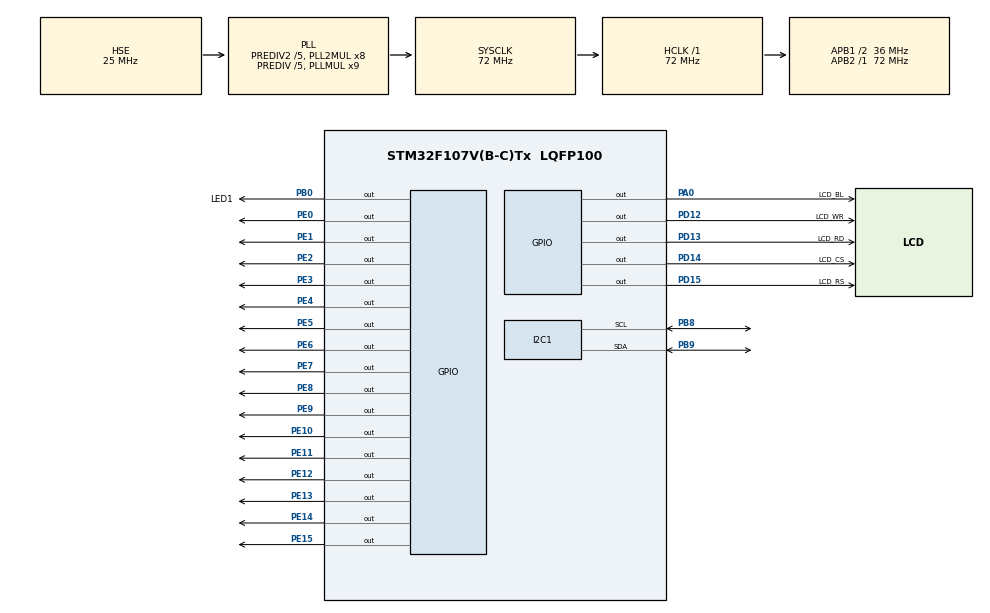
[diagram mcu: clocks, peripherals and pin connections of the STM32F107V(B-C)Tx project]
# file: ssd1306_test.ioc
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I2C1.I2C_Mode=I2C_Fast
Mcu.Family=STM32F1
Mcu.Name=STM32F107V(B-C)Tx
Mcu.Package=LQFP100
NVIC.PriorityGroup=NVIC_PRIORITYGROUP_4
OSC_IN.Mode=HSE-External-Oscillator
OSC_IN.Signal=RCC_OSC_IN
OSC_OUT.Mode=HSE-External-Oscillator
OSC_OUT.Signal=RCC_OSC_OUT
PA0-WKUP.GPIO_Label=LCD_BL
PA0-WKUP.GPIO_PuPd=GPIO_PULLDOWN
PA0-WKUP.Signal=GPIO_Output
PA13.Mode=Serial_Wire
PA13.Signal=SYS_JTMS-SWDIO
PA14.Mode=Serial_Wire
PA14.Signal=SYS_JTCK-SWCLK
PB0.GPIO_Label=LED1
PB0.Signal=GPIO_Output
PB8.Mode=I2C
PB8.Signal=I2C1_SCL
PB9.Mode=I2C
PB9.Signal=I2C1_SDA
PD12.GPIO_Label=LCD_WR
PD12.Signal=GPIO_Output
PD13.GPIO_Label=LCD_RD
PD13.Signal=GPIO_Output
PD14.GPIO_Label=LCD_CS
PD14.Signal=GPIO_Output
PD15.GPIO_Label=LCD_RS
PD15.Signal=GPIO_Output
PE0.Signal=GPIO_Output
PE1.Signal=GPIO_Output
PE10.Signal=GPIO_Output
PE11.Signal=GPIO_Output
PE12.Signal=GPIO_Output
PE13.Signal=GPIO_Output
PE14.Signal=GPIO_Output
PE15.Signal=GPIO_Output
PE2.Signal=GPIO_Output
PE3.Signal=GPIO_Output
PE4.Signal=GPIO_Output
PE5.Signal=GPIO_Output
PE6.Signal=GPIO_Output
PE7.Signal=GPIO_Output
PE8.Signal=GPIO_Output
PE9.Signal=GPIO_Output
ProjectManager.HeapSize=0x200
ProjectManager.StackSize=0x400
ProjectManager.TargetToolchain=TrueSTUDIO
RCC.AHBFreq_Value=72000000
RCC.APB1CLKDivider=RCC_HCLK_DIV2
RCC.APB1Freq_Value=36000000
RCC.APB1TimFreq_Value=72000000
RCC.APB2Freq_Value=72000000
RCC.APB2TimFreq_Value=72000000
RCC.HCLKFreq_Value=72000000
RCC.HSEDivPLL=RCC_HSE_PREDIV_DIV5
RCC.HSE_VALUE=25000000
RCC.PLLMUL=RCC_PLL_MUL9
RCC.PLLSourceVirtual=RCC_PLLSOURCE_HSE
RCC.Prediv1Source=RCC_PREDIV1_SOURCE_PLL2
RCC.Prediv2=RCC_HSE_PREDIV2_DIV5
RCC.SYSCLKFreq_VALUE=72000000
RCC.SYSCLKSource=RCC_SYSCLKSOURCE_PLLCLK
RCC.USBFreq_Value=48000000
board=custom

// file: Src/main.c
/**
  ******************************************************************************
  * @file           : main.c
  * @brief          : Main program body
  ******************************************************************************
  ** This notice applies to any and all portions of this file
  * that are not between comment pairs USER CODE BEGIN and
  * USER CODE END. Other portions of this file, whether
  * inserted by the user or by software development tools
  * are owned by their respective copyright owners.
  *
  * COPYRIGHT(c) 2018 STMicroelectronics
  *
  * Redistribution and use in source and binary forms, with or without modification,
  * are permitted provided that the following conditions are met:
  *   1. Redistributions of source code must retain the above copyright notice,
  *      this list of conditions and the following disclaimer.
  *   2. Redistributions in binary form must reproduce the above copyright notice,
  *      this list of conditions and the following disclaimer in the documentation
  *      and/or other materials provided with the distribution.
  *   3. Neither the name of STMicroelectronics nor the names of its contributors
  *      may be used to endorse or promote products derived from this software
  *      without specific prior written permission.
  *
  * THIS SOFTWARE IS PROVIDED BY THE COPYRIGHT HOLDERS AND CONTRIBUTORS "AS IS"
  * AND ANY EXPRESS OR IMPLIED WARRANTIES, INCLUDING, BUT NOT LIMITED TO, THE
  * IMPLIED WARRANTIES OF MERCHANTABILITY AND FITNESS FOR A PARTICULAR PURPOSE ARE
  * DISCLAIMED. IN NO EVENT SHALL THE COPYRIGHT HOLDER OR CONTRIBUTORS BE LIABLE
  * FOR ANY DIRECT, INDIRECT, INCIDENTAL, SPECIAL, EXEMPLARY, OR CONSEQUENTIAL
  * DAMAGES (INCLUDING, BUT NOT LIMITED TO, PROCUREMENT OF SUBSTITUTE GOODS OR
  * SERVICES; LOSS OF USE, DATA, OR PROFITS; OR BUSINESS INTERRUPTION) HOWEVER
  * CAUSED AND ON ANY THEORY OF LIABILITY, WHETHER IN CONTRACT, STRICT LIABILITY,
  * OR TORT (INCLUDING NEGLIGENCE OR OTHERWISE) ARISING IN ANY WAY OUT OF THE USE
  * OF THIS SOFTWARE, EVEN IF ADVISED OF THE POSSIBILITY OF SUCH DAMAGE.
  *
  ******************************************************************************
  */
#include "main.h"
#include "stm32f1xx_hal.h"

/* USER CODE BEGIN Includes */
#include "app.h"
/* USER CODE END Includes */

I2C_HandleTypeDef hi2c1;

/* USER CODE BEGIN PV */
/* Private variables ---------------------------------------------------------*/

/* USER CODE END PV */

void SystemClock_Config(void);
static void MX_GPIO_Init(void);
static void MX_I2C1_Init(void);

/* USER CODE BEGIN PFP */
/* Private function prototypes -----------------------------------------------*/

/* USER CODE END PFP */

int main(void)
{

  /* MCU Configuration----------------------------------------------------------*/

  /* Reset of all peripherals, Initializes the Flash interface and the Systick. */
  HAL_Init();

  /* Configure the system clock */
  SystemClock_Config();

  /* Initialize all configured peripherals */
  MX_GPIO_Init();
  MX_I2C1_Init();
  /* USER CODE BEGIN 2 */
  app_init();
  /* USER CODE END 2 */

  /* Infinite loop */
  while (1)
  {

  /* USER CODE BEGIN 3 */
	app_step();
  }
  /* USER CODE END 3 */

}

void SystemClock_Config(void)
{

  RCC_OscInitTypeDef RCC_OscInitStruct;
  RCC_ClkInitTypeDef RCC_ClkInitStruct;

    /**Initializes the CPU, AHB and APB busses clocks
    */
  RCC_OscInitStruct.OscillatorType = RCC_OSCILLATORTYPE_HSE;
  RCC_OscInitStruct.HSEState = RCC_HSE_ON;
  RCC_OscInitStruct.HSEPredivValue = RCC_HSE_PREDIV_DIV5;
  RCC_OscInitStruct.HSIState = RCC_HSI_ON;
  RCC_OscInitStruct.Prediv1Source = RCC_PREDIV1_SOURCE_PLL2;
  RCC_OscInitStruct.PLL.PLLState = RCC_PLL_ON;
  RCC_OscInitStruct.PLL.PLLSource = RCC_PLLSOURCE_HSE;
  RCC_OscInitStruct.PLL.PLLMUL = RCC_PLL_MUL9;
  RCC_OscInitStruct.PLL2.PLL2State = RCC_PLL2_ON;
  RCC_OscInitStruct.PLL2.PLL2MUL = RCC_PLL2_MUL8;
  RCC_OscInitStruct.PLL2.HSEPrediv2Value = RCC_HSE_PREDIV2_DIV5;
  if (HAL_RCC_OscConfig(&RCC_OscInitStruct) != HAL_OK)
  {
    _Error_Handler(__FILE__, __LINE__);
  }

    /**Initializes the CPU, AHB and APB busses clocks
    */
  RCC_ClkInitStruct.ClockType = RCC_CLOCKTYPE_HCLK|RCC_CLOCKTYPE_SYSCLK
                              |RCC_CLOCKTYPE_PCLK1|RCC_CLOCKTYPE_PCLK2;
  RCC_ClkInitStruct.SYSCLKSource = RCC_SYSCLKSOURCE_PLLCLK;
  RCC_ClkInitStruct.AHBCLKDivider = RCC_SYSCLK_DIV1;
  RCC_ClkInitStruct.APB1CLKDivider = RCC_HCLK_DIV2;
  RCC_ClkInitStruct.APB2CLKDivider = RCC_HCLK_DIV1;

  if (HAL_RCC_ClockConfig(&RCC_ClkInitStruct, FLASH_LATENCY_2) != HAL_OK)
  {
    _Error_Handler(__FILE__, __LINE__);
  }

    /**Configure the Systick interrupt time
    */
  HAL_SYSTICK_Config(HAL_RCC_GetHCLKFreq()/1000);

    /**Configure the Systick
    */
  HAL_SYSTICK_CLKSourceConfig(SYSTICK_CLKSOURCE_HCLK);

    /**Configure the Systick interrupt time
    */
  __HAL_RCC_PLLI2S_ENABLE();

  /* SysTick_IRQn interrupt configuration */
  HAL_NVIC_SetPriority(SysTick_IRQn, 0, 0);
}

/* I2C1 init function */
static void MX_I2C1_Init(void)
{

  hi2c1.Instance = I2C1;
  hi2c1.Init.ClockSpeed = 400000;
  hi2c1.Init.DutyCycle = I2C_DUTYCYCLE_2;
  hi2c1.Init.OwnAddress1 = 0;
  hi2c1.Init.AddressingMode = I2C_ADDRESSINGMODE_7BIT;
  hi2c1.Init.DualAddressMode = I2C_DUALADDRESS_DISABLE;
  hi2c1.Init.OwnAddress2 = 0;
  hi2c1.Init.GeneralCallMode = I2C_GENERALCALL_DISABLE;
  hi2c1.Init.NoStretchMode = I2C_NOSTRETCH_DISABLE;
  if (HAL_I2C_Init(&hi2c1) != HAL_OK)
  {
    _Error_Handler(__FILE__, __LINE__);
  }

}

/** Configure pins as
        * Analog
        * Input
        * Output
        * EVENT_OUT
        * EXTI
*/
static void MX_GPIO_Init(void)
{

  GPIO_InitTypeDef GPIO_InitStruct;

  /* GPIO Ports Clock Enable */
  __HAL_RCC_GPIOE_CLK_ENABLE();
  __HAL_RCC_GPIOA_CLK_ENABLE();
  __HAL_RCC_GPIOB_CLK_ENABLE();
  __HAL_RCC_GPIOD_CLK_ENABLE();

  /*Configure GPIO pin Output Level */
  HAL_GPIO_WritePin(GPIOE, GPIO_PIN_2|GPIO_PIN_3|GPIO_PIN_4|GPIO_PIN_5
                          |GPIO_PIN_6|GPIO_PIN_7|GPIO_PIN_8|GPIO_PIN_9
                          |GPIO_PIN_10|GPIO_PIN_11|GPIO_PIN_12|GPIO_PIN_13
                          |GPIO_PIN_14|GPIO_PIN_15|GPIO_PIN_0|GPIO_PIN_1, GPIO_PIN_RESET);

  /*Configure GPIO pin Output Level */
  HAL_GPIO_WritePin(LCD_BL_GPIO_Port, LCD_BL_Pin, GPIO_PIN_RESET);

  /*Configure GPIO pin Output Level */
  HAL_GPIO_WritePin(LED1_GPIO_Port, LED1_Pin, GPIO_PIN_RESET);

  /*Configure GPIO pin Output Level */
  HAL_GPIO_WritePin(GPIOD, LCD_WR_Pin|LCD_RD_Pin|LCD_CS_Pin|LCD_RS_Pin, GPIO_PIN_RESET);

  /*Configure GPIO pins : PE2 PE3 PE4 PE5
                           PE6 PE7 PE8 PE9
                           PE10 PE11 PE12 PE13
                           PE14 PE15 PE0 PE1 */
  GPIO_InitStruct.Pin = GPIO_PIN_2|GPIO_PIN_3|GPIO_PIN_4|GPIO_PIN_5
                          |GPIO_PIN_6|GPIO_PIN_7|GPIO_PIN_8|GPIO_PIN_9
                          |GPIO_PIN_10|GPIO_PIN_11|GPIO_PIN_12|GPIO_PIN_13
                          |GPIO_PIN_14|GPIO_PIN_15|GPIO_PIN_0|GPIO_PIN_1;
  GPIO_InitStruct.Mode = GPIO_MODE_OUTPUT_PP;
  GPIO_InitStruct.Pull = GPIO_NOPULL;
  GPIO_InitStruct.Speed = GPIO_SPEED_FREQ_LOW;
  HAL_GPIO_Init(GPIOE, &GPIO_InitStruct);

  /*Configure GPIO pin : LCD_BL_Pin */
  GPIO_InitStruct.Pin = LCD_BL_Pin;
  GPIO_InitStruct.Mode = GPIO_MODE_OUTPUT_PP;
  GPIO_InitStruct.Pull = GPIO_PULLDOWN;
  GPIO_InitStruct.Speed = GPIO_SPEED_FREQ_LOW;
  HAL_GPIO_Init(LCD_BL_GPIO_Port, &GPIO_InitStruct);

  /*Configure GPIO pin : LED1_Pin */
  GPIO_InitStruct.Pin = LED1_Pin;
  GPIO_InitStruct.Mode = GPIO_MODE_OUTPUT_PP;
  GPIO_InitStruct.Pull = GPIO_NOPULL;
  GPIO_InitStruct.Speed = GPIO_SPEED_FREQ_LOW;
  HAL_GPIO_Init(LED1_GPIO_Port, &GPIO_InitStruct);

  /*Configure GPIO pins : LCD_WR_Pin LCD_RD_Pin LCD_CS_Pin LCD_RS_Pin */
  GPIO_InitStruct.Pin = LCD_WR_Pin|LCD_RD_Pin|LCD_CS_Pin|LCD_RS_Pin;
  GPIO_InitStruct.Mode = GPIO_MODE_OUTPUT_PP;
  GPIO_InitStruct.Pull = GPIO_NOPULL;
  GPIO_InitStruct.Speed = GPIO_SPEED_FREQ_LOW;
  HAL_GPIO_Init(GPIOD, &GPIO_InitStruct);

}

void _Error_Handler(char *file, int line)
{
  while(1)
  {
  }
}

/************************ (C) COPYRIGHT STMicroelectronics *****END OF FILE****/
